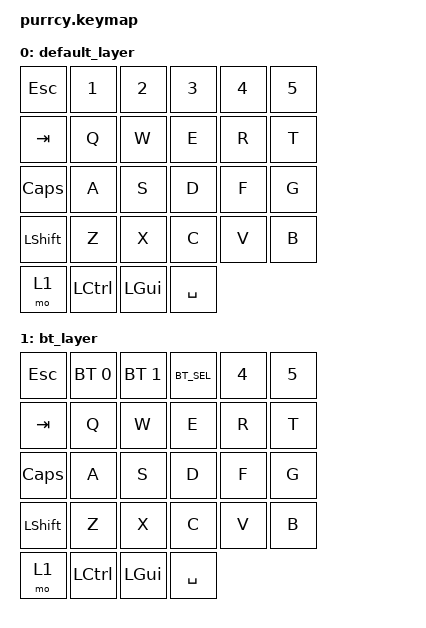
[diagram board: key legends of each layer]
#include <behaviors.dtsi>
#include <dt-bindings/zmk/keys.h>
#include <dt-bindings/zmk/bt.h>

/ {
    keymap {
        compatible = "zmk,keymap";

        default_layer {
            bindings = <
                &kp ESC      &kp N1       &kp N2       &kp N3       &kp N4       &kp N5
                &kp TAB      &kp Q        &kp W        &kp E        &kp R        &kp T
                &kp CLCK     &kp A        &kp S        &kp D        &kp F        &kp G
                &kp LSHFT    &kp Z        &kp X        &kp C        &kp V        &kp B
                &mo 1        &kp LCTRL    &kp LGUI     &kp SPACE
            >;
        };
        bt_layer {
            bindings = <
                &kp ESC      &bt BT_SEL 0 &bt BT_SEL 1 &kp BT_SEL 2 &kp N4       &kp N5
                &kp TAB      &kp Q        &kp W        &kp E        &kp R        &kp T
                &kp CLCK     &kp A        &kp S        &kp D        &kp F        &kp G
                &kp LSHFT    &kp Z        &kp X        &kp C        &kp V        &kp B
                &mo 1        &kp LCTRL    &kp LGUI     &kp SPACE
            >;
        };
        
    };
};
